# ATSAM4N16C device description
Architecture: CORTEX-M4; Family: SAM4; Series: SAM4N
Registers are 32-bit, read-write, no defined reset value unless marked. A register's access mark holds for its fields unless they carry their own. Offsets are from the block's base; [hi:lo] are bit positions; {n}, {i} and the like mark numbered series.

## RSTC — Reset Controller
Instances: RSTC 0x400E1400
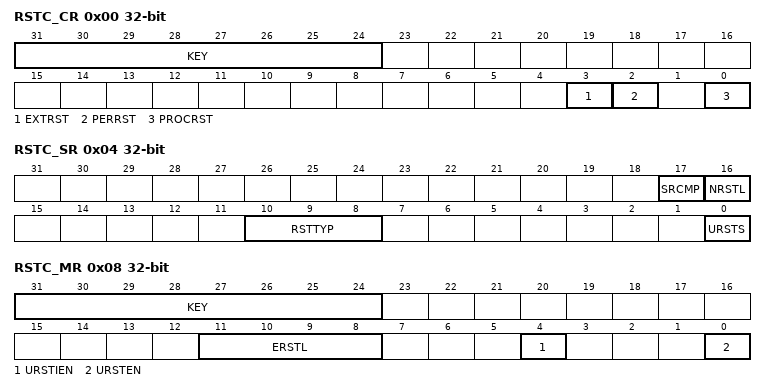
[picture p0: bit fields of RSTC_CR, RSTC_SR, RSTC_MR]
0x00 RSTC_CR wo — Control Register
  [31:24] KEY — System Reset Key
    165=PASSWD (Writing any other value in this field aborts the write operation.)
  [3] EXTRST — External Reset
  [2] PERRST — Peripheral Reset
  [0] PROCRST — Processor Reset
0x04 RSTC_SR ro — Status Register
  [17] SRCMP — Software Reset Command in Progress
  [16] NRSTL — NRST Pin Level
  [10:8] RSTTYP — Reset Type
    0=GeneralReset (First power-up Reset); 1=BackupReset (Return from Backup Mode); 2=WatchdogReset (Watchdog fault occurred); 3=SoftwareReset (Processor reset required by the software); 4=UserReset (NRST pin detected low)
  [0] URSTS — User Reset Status
0x08 RSTC_MR — Mode Register
  [31:24] KEY — Write Access Password
    165=PASSWD (Writing any other value in this field aborts the write operation.Always reads as 0.)
  [11:8] ERSTL — External Reset Length
  [4] URSTIEN — User Reset Interrupt Enable
  [0] URSTEN — User Reset Enable

## RTT — Real-time Timer
Instances: RTT 0x400E1430
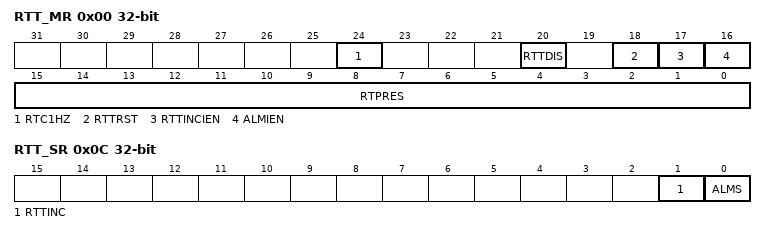
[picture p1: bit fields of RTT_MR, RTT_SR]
0x00 RTT_MR — Mode Register
  [24] RTC1HZ — Real-Time Clock 1Hz Clock Selection
  [20] RTTDIS — Real-time Timer Disable
  [18] RTTRST — Real-time Timer Restart
  [17] RTTINCIEN — Real-time Timer Increment Interrupt Enable
  [16] ALMIEN — Alarm Interrupt Enable
  [15:0] RTPRES — Real-time Timer Prescaler Value
0x04 RTT_AR — Alarm Register
  [31:0] ALMV — Alarm Value
0x08 RTT_VR ro — Value Register
  [31:0] CRTV — Current Real-time Value
0x0C RTT_SR ro — Status Register
  [1] RTTINC — Real-time Timer Increment
  [0] ALMS — Real-time Alarm Status

## WDT — Watchdog Timer
Instances: WDT 0x400E1450
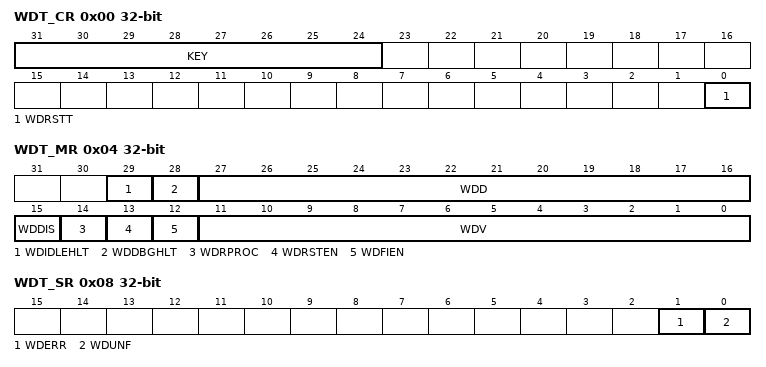
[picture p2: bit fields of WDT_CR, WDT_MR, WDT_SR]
0x00 WDT_CR wo — Control Register
  [31:24] KEY — Password.
    165=PASSWD (Writing any other value in this field aborts the write operation.)
  [0] WDRSTT — Watchdog Restart
0x04 WDT_MR — Mode Register
  [29] WDIDLEHLT — Watchdog Idle Halt
  [28] WDDBGHLT — Watchdog Debug Halt
  [27:16] WDD — Watchdog Delta Value
  [15] WDDIS — Watchdog Disable
  [14] WDRPROC — Watchdog Reset Processor
  [13] WDRSTEN — Watchdog Reset Enable
  [12] WDFIEN — Watchdog Fault Interrupt Enable
  [11:0] WDV — Watchdog Counter Value
0x08 WDT_SR ro — Status Register
  [1] WDERR — Watchdog Error
  [0] WDUNF — Watchdog Underflow

## GPNVMBITS (FUSES module)
Instances: GPNVMBITS 0 in fuses
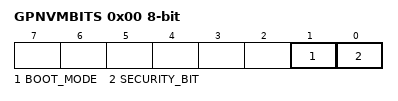
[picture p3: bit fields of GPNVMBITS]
0x00 GPNVMBITS 8-bit
  [1] BOOT_MODE — Boot Mode Selection
  [0] SECURITY_BIT ro

## LOCKBIT
Instances: LOCKBIT 0 in lockbits
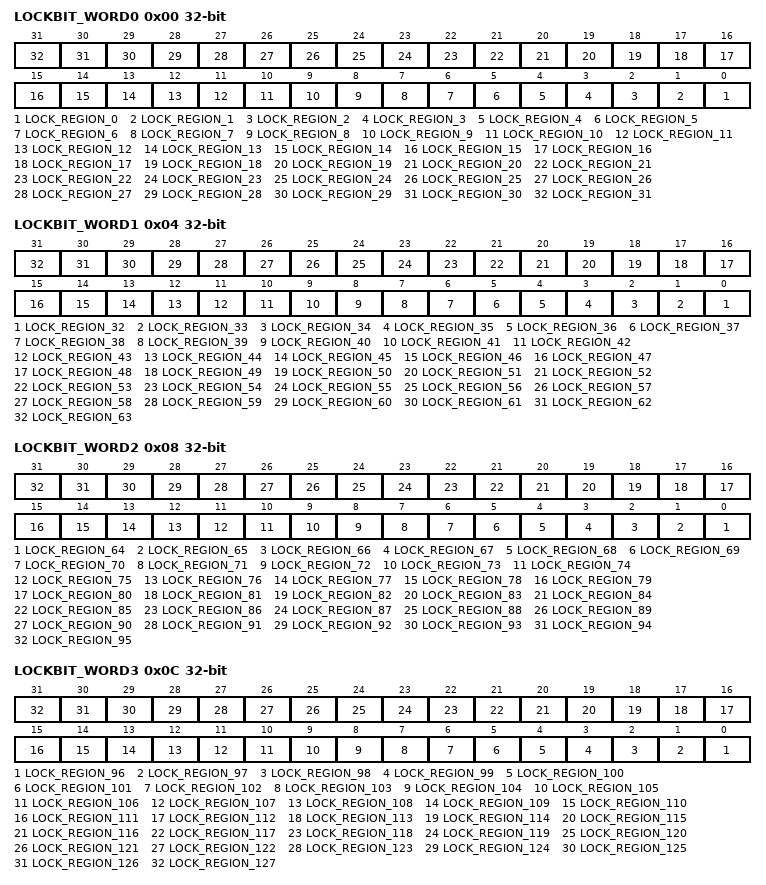
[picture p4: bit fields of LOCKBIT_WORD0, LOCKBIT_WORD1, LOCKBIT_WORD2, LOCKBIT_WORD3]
0x00 LOCKBIT_WORD0 — Lock Bits Word 0
  [n] LOCK_REGION_{n} (n=0..31)
0x04 LOCKBIT_WORD1 — Lock Bits Word 1
  [n-32] LOCK_REGION_{n} (n=32..63)
0x08 LOCKBIT_WORD2 — Lock Bits Word 2
  [n-64] LOCK_REGION_{n} (n=64..95)
0x0C LOCKBIT_WORD3 — Lock Bits Word 3
  [n-96] LOCK_REGION_{n} (n=96..127)

## SysTick — System timer
Instances: SysTick 0xE000E010
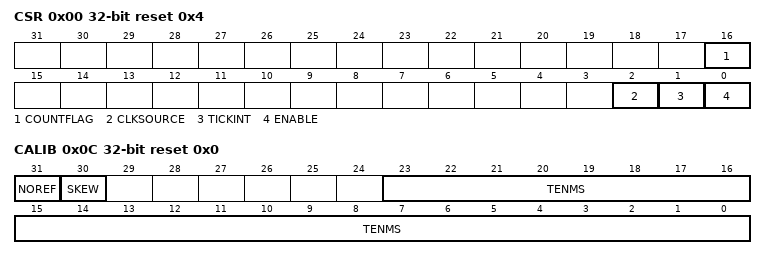
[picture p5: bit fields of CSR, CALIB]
0x00 CSR access not given reset 0x4 — SysTick Control and Status Register
  [16] COUNTFLAG
  [2] CLKSOURCE
    0=external clock; 1=processor clock
  [1] TICKINT
    0=counting down to 0 does not assert the SysTick exception request; 1=counting down to 0 asserts the SysTick exception request
  [0] ENABLE
    0=counter disabled; 1=counter enabled
0x04 RVR access not given reset 0x0 — SysTick Reload Value Register
  [23:0] RELOAD — Value to load into the SysTick Current Value Register when the counter reaches 0
0x08 CVR access not given reset 0x0 — SysTick Current Value Register
  [23:0] CURRENT — Current value at the time the register is accessed
0x0C CALIB access not given reset 0x0 — SysTick Calibration Value Register
  [31] NOREF
    0=The reference clock is provided; 1=The reference clock is not provided
  [30] SKEW
    0=10ms calibration value is exact; 1=10ms calibration value is inexact, because of the clock frequency
  [23:0] TENMS — Reload value to use for 10ms timing

## NVIC — Nested Vectored Interrupt Controller
Instances: NVIC 0xE000E100
{0x0+4i} NVICISER{i} access not given reset 0x0 (i=0..3) — Interrupt Set Enable Register n
  [31:0] SETENA — Interrupt set enable bits
{0x80+4i} NVICICER{i} access not given reset 0x0 (i=0..3) — Interrupt Clear Enable Register n
  [31:0] CLRENA — Interrupt clear-enable bits
{0x100+4i} NVICISPR{i} access not given reset 0x0 (i=0..3) — Interrupt Set Pending Register n
  [31:0] SETPEND — Interrupt set-pending bits
{0x180+4i} NVICICPR{i} access not given reset 0x0 (i=0..3) — Interrupt Clear Pending Register n
  [31:0] CLRPEND — Interrupt clear-pending bits
{0x200+4i} NVICIABR{i} access not given reset 0x0 (i=0..3) — Interrupt Active bit Register n
  [31:0] ACTIVE — Interrupt active flags
{0x300+i} NVICIP{i} 8-bit access not given reset 0x0 (i=0..105) — Interrupt Priority Register n
  [7:0] PRI{i} — Priority of interrupt {i}
0xE00 NVICSTIR access not given reset 0x0 — Software Trigger Interrupt Register
  [8:0] INTID — Interrupt ID of the interrupt to trigger, in the range 0-239. For example, a value of 0x03 specifies interrupt IRQ3.

## MPU — Memory Protection Unit
Instances: MPU 0xE000ED90
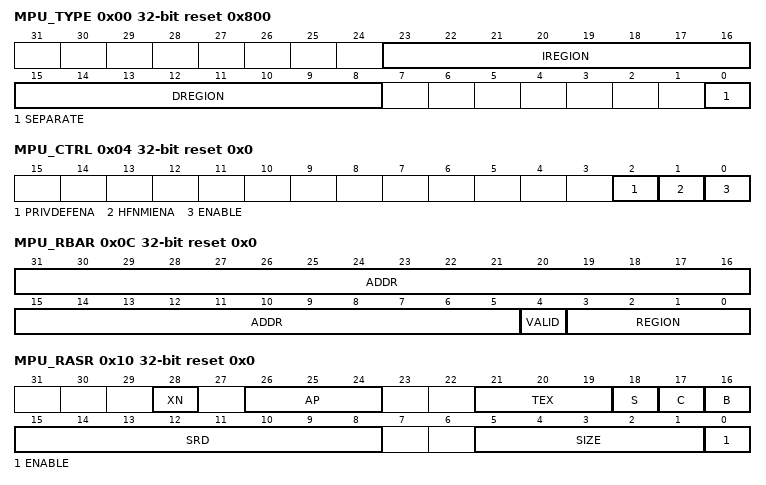
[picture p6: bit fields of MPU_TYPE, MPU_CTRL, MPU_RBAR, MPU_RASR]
0x00 MPU_TYPE ro reset 0x800
  [23:16] IREGION — Indicates the number of supported MPU data regions.
  [15:8] DREGION — Indicates the number of supported MPU instruction regions.
  [0] SEPARATE — Indicates support for unified or separate instruction and date memory maps.
0x04 MPU_CTRL reset 0x0 — MPU Control Register
  [2] PRIVDEFENA — Enables privileged software access to the default memory map.
  [1] HFNMIENA — Enables the operation of MPU during hard fault, NMI, and FAULTMASK handlers.
  [0] ENABLE — Enables the MPU
0x08 MPU_RNR reset 0x0 — MPU Region Number Register
  [7:0] REGION — Indicates the MPU region referenced by the MPU_RBAR and MPU_RASR registers.
0x0C MPU_RBAR reset 0x0 — MPU Region Base Address Register
  [31:5] ADDR — Region base address field.
  [4] VALID — MPU Region Number valid bit.
  [3:0] REGION — MPU region field.
0x10 MPU_RASR reset 0x0 — MPU Region Attribute and Size Register
  [28] XN — Instruction access disable bit.
  [26:24] AP — Access permission field.
  [21:19] TEX — MPU access permission attributes.
  [18] S — Shareable bit.
  [17] C — MPU access permission attributes.
  [16] B — MPU access permission attributes.
  [15:8] SRD — Subregion disable bits.
  [5:1] SIZE — Specifies the size of the MPU protection region.
  [0] ENABLE — Region enable bit.
